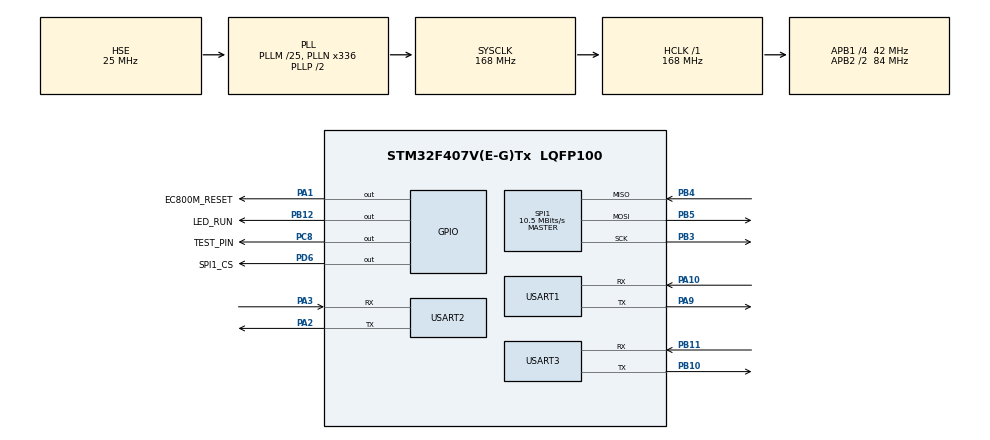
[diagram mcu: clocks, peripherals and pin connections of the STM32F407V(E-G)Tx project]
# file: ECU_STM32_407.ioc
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Dma.Request0=USART1_TX
Dma.Request1=USART2_TX
Dma.Request2=USART3_TX
Dma.USART1_TX.0.Direction=DMA_MEMORY_TO_PERIPH
Dma.USART1_TX.0.FIFOMode=DMA_FIFOMODE_DISABLE
Dma.USART1_TX.0.Instance=DMA2_Stream7
Dma.USART1_TX.0.MemDataAlignment=DMA_MDATAALIGN_BYTE
Dma.USART1_TX.0.MemInc=DMA_MINC_ENABLE
Dma.USART1_TX.0.Mode=DMA_NORMAL
Dma.USART1_TX.0.PeriphDataAlignment=DMA_PDATAALIGN_BYTE
Dma.USART1_TX.0.PeriphInc=DMA_PINC_DISABLE
Dma.USART1_TX.0.Priority=DMA_PRIORITY_LOW
Dma.USART2_TX.1.Direction=DMA_MEMORY_TO_PERIPH
Dma.USART2_TX.1.FIFOMode=DMA_FIFOMODE_DISABLE
Dma.USART2_TX.1.Instance=DMA1_Stream6
Dma.USART2_TX.1.MemDataAlignment=DMA_MDATAALIGN_BYTE
Dma.USART2_TX.1.MemInc=DMA_MINC_ENABLE
Dma.USART2_TX.1.Mode=DMA_NORMAL
Dma.USART2_TX.1.PeriphDataAlignment=DMA_PDATAALIGN_BYTE
Dma.USART2_TX.1.PeriphInc=DMA_PINC_DISABLE
Dma.USART2_TX.1.Priority=DMA_PRIORITY_LOW
Dma.USART3_TX.2.Direction=DMA_MEMORY_TO_PERIPH
Dma.USART3_TX.2.FIFOMode=DMA_FIFOMODE_DISABLE
Dma.USART3_TX.2.Instance=DMA1_Stream3
Dma.USART3_TX.2.MemDataAlignment=DMA_MDATAALIGN_BYTE
Dma.USART3_TX.2.MemInc=DMA_MINC_ENABLE
Dma.USART3_TX.2.Mode=DMA_NORMAL
Dma.USART3_TX.2.PeriphDataAlignment=DMA_PDATAALIGN_BYTE
Dma.USART3_TX.2.PeriphInc=DMA_PINC_DISABLE
Dma.USART3_TX.2.Priority=DMA_PRIORITY_LOW
FREERTOS.Tasks01=defaultTask,0,128,StartDefaultTask,Default,NULL,Dynamic,NULL,NULL;led_task,-2,128,led_task_handle,Default,NULL,Dynamic,NULL,NULL
FREERTOS.configTIMER_TASK_STACK_DEPTH=1024
FREERTOS.configTOTAL_HEAP_SIZE=0x10000
FREERTOS.configUSE_TIMERS=1
Mcu.Family=STM32F4
Mcu.Name=STM32F407V(E-G)Tx
Mcu.Package=LQFP100
NVIC.DMA1_Stream3_IRQn=true\:5\:0\:false\:false\:true\:true\:false\:true\:true
NVIC.DMA1_Stream6_IRQn=true\:5\:0\:false\:false\:true\:true\:false\:true\:true
NVIC.DMA2_Stream7_IRQn=true\:5\:0\:false\:false\:true\:true\:false\:true\:true
NVIC.PriorityGroup=NVIC_PRIORITYGROUP_4
NVIC.SPI1_IRQn=true\:5\:0\:false\:false\:true\:true\:true\:true\:true
NVIC.USART1_IRQn=true\:5\:0\:false\:false\:true\:true\:true\:true\:true
NVIC.USART2_IRQn=true\:5\:0\:false\:false\:true\:true\:true\:true\:true
NVIC.USART3_IRQn=true\:5\:0\:false\:false\:true\:true\:true\:true\:true
PA1.GPIO_Label=EC800M_RESET
PA1.GPIO_ModeDefaultOutputPP=GPIO_MODE_OUTPUT_PP
PA1.GPIO_PuPd=GPIO_PULLUP
PA1.PinState=GPIO_PIN_SET
PA1.Signal=GPIO_Output
PA10.Mode=Asynchronous
PA10.Signal=USART1_RX
PA13.Mode=Serial_Wire
PA13.Signal=SYS_JTMS-SWDIO
PA14.Mode=Serial_Wire
PA14.Signal=SYS_JTCK-SWCLK
PA2.Mode=Asynchronous
PA2.Signal=USART2_TX
PA3.Mode=Asynchronous
PA3.Signal=USART2_RX
PA9.Mode=Asynchronous
PA9.Signal=USART1_TX
PB10.Mode=Asynchronous
PB10.Signal=USART3_TX
PB11.Mode=Asynchronous
PB11.Signal=USART3_RX
PB12.GPIO_Label=LED_RUN
PB12.Signal=GPIO_Output
PB3.Mode=Full_Duplex_Master
PB3.Signal=SPI1_SCK
PB4.Mode=Full_Duplex_Master
PB4.Signal=SPI1_MISO
PB5.Mode=Full_Duplex_Master
PB5.Signal=SPI1_MOSI
PC14-OSC32_IN.Mode=LSE-External-Oscillator
PC14-OSC32_IN.Signal=RCC_OSC32_IN
PC15-OSC32_OUT.Mode=LSE-External-Oscillator
PC15-OSC32_OUT.Signal=RCC_OSC32_OUT
PC8.GPIO_Label=TEST_PIN
PC8.GPIO_PuPd=GPIO_PULLUP
PC8.GPIO_Speed=GPIO_SPEED_FREQ_VERY_HIGH
PC8.Signal=GPIO_Output
PD6.GPIO_Label=SPI1_CS
PD6.GPIO_PuPd=GPIO_PULLUP
PD6.GPIO_Speed=GPIO_SPEED_FREQ_VERY_HIGH
PD6.Signal=GPIO_Output
PH0-OSC_IN.Mode=HSE-External-Oscillator
PH0-OSC_IN.Signal=RCC_OSC_IN
PH1-OSC_OUT.Mode=HSE-External-Oscillator
PH1-OSC_OUT.Signal=RCC_OSC_OUT
ProjectManager.HeapSize=0x800
ProjectManager.StackSize=0x800
ProjectManager.TargetToolchain=EWARM V8.50
RCC.48MHZClocksFreq_Value=48000000
RCC.AHBFreq_Value=168000000
RCC.APB1CLKDivider=RCC_HCLK_DIV4
RCC.APB1Freq_Value=42000000
RCC.APB1TimFreq_Value=84000000
RCC.APB2CLKDivider=RCC_HCLK_DIV2
RCC.APB2Freq_Value=84000000
RCC.APB2TimFreq_Value=168000000
RCC.CortexFreq_Value=168000000
RCC.HCLKFreq_Value=168000000
RCC.HSE_VALUE=25000000
RCC.HSI_VALUE=16000000
RCC.PLLM=25
RCC.PLLN=336
RCC.PLLQ=7
RCC.PLLSourceVirtual=RCC_PLLSOURCE_HSE
RCC.SYSCLKFreq_VALUE=168000000
RCC.SYSCLKSource=RCC_SYSCLKSOURCE_PLLCLK
RCC.VCOOutputFreq_Value=336000000
SPI1.BaudRatePrescaler=SPI_BAUDRATEPRESCALER_8
SPI1.CRCCalculation=SPI_CRCCALCULATION_DISABLE
SPI1.CalculateBaudRate=10.5 MBits/s
SPI1.Direction=SPI_DIRECTION_2LINES
SPI1.Mode=SPI_MODE_MASTER
SPI1.VirtualType=VM_MASTER
USART1.VirtualMode=VM_ASYNC
USART2.VirtualMode=VM_ASYNC
USART3.VirtualMode=VM_ASYNC
VP_FREERTOS_VS_CMSIS_V1.Mode=CMSIS_V1
VP_RTC_VS_RTC_Activate.Mode=RTC_Enabled
VP_RTC_VS_RTC_Calendar.Mode=RTC_Calendar
board=custom

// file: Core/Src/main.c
/* USER CODE BEGIN Header */
/**
  ******************************************************************************
  * @file           : main.c
  * @brief          : Main program body
  ******************************************************************************
  * @attention
  *
  * Copyright (c) 2024 STMicroelectronics.
  * All rights reserved.
  *
  * This software is licensed under terms that can be found in the LICENSE file
  * in the root directory of this software component.
  * If no LICENSE file comes with this software, it is provided AS-IS.
  *
  ******************************************************************************
  */
/* USER CODE END Header */
#include "main.h"
#include "cmsis_os.h"
#include "dma.h"
#include "rtc.h"
#include "spi.h"
#include "usart.h"
#include "gpio.h"

void SystemClock_Config(void);
void MX_FREERTOS_Init(void);

int main(void)
{

  /* MCU Configuration--------------------------------------------------------*/

  /* Reset of all peripherals, Initializes the Flash interface and the Systick. */
  HAL_Init();

  /* Configure the system clock */
  SystemClock_Config();

  /* USER CODE BEGIN SysInit */
  __HAL_RCC_BKPSRAM_CLK_ENABLE();
  /* USER CODE END SysInit */

  /* Initialize all configured peripherals */
  MX_GPIO_Init();
  MX_DMA_Init();
  MX_USART1_UART_Init();
  MX_USART2_UART_Init();
  MX_USART3_UART_Init();
  MX_RTC_Init();
  MX_SPI1_Init();

  /* Call init function for freertos objects (in cmsis_os2.c) */
  MX_FREERTOS_Init();

  /* Start scheduler */
  osKernelStart();

  /* We should never get here as control is now taken by the scheduler */

  /* Infinite loop */
  while (1)
  {

  }
}

void SystemClock_Config(void)
{
  RCC_OscInitTypeDef RCC_OscInitStruct = {0};
  RCC_ClkInitTypeDef RCC_ClkInitStruct = {0};

  /** Configure the main internal regulator output voltage
  */
  __HAL_RCC_PWR_CLK_ENABLE();
  __HAL_PWR_VOLTAGESCALING_CONFIG(PWR_REGULATOR_VOLTAGE_SCALE1);

  /** Initializes the RCC Oscillators according to the specified parameters
  * in the RCC_OscInitTypeDef structure.
  */
  RCC_OscInitStruct.OscillatorType = RCC_OSCILLATORTYPE_LSI|RCC_OSCILLATORTYPE_HSE;
  RCC_OscInitStruct.HSEState = RCC_HSE_ON;
  RCC_OscInitStruct.LSIState = RCC_LSI_ON;
  RCC_OscInitStruct.PLL.PLLState = RCC_PLL_ON;
  RCC_OscInitStruct.PLL.PLLSource = RCC_PLLSOURCE_HSE;
  RCC_OscInitStruct.PLL.PLLM = 25;
  RCC_OscInitStruct.PLL.PLLN = 336;
  RCC_OscInitStruct.PLL.PLLP = RCC_PLLP_DIV2;
  RCC_OscInitStruct.PLL.PLLQ = 7;
  if (HAL_RCC_OscConfig(&RCC_OscInitStruct) != HAL_OK)
  {
    Error_Handler();
  }

  /** Initializes the CPU, AHB and APB buses clocks
  */
  RCC_ClkInitStruct.ClockType = RCC_CLOCKTYPE_HCLK|RCC_CLOCKTYPE_SYSCLK
                              |RCC_CLOCKTYPE_PCLK1|RCC_CLOCKTYPE_PCLK2;
  RCC_ClkInitStruct.SYSCLKSource = RCC_SYSCLKSOURCE_PLLCLK;
  RCC_ClkInitStruct.AHBCLKDivider = RCC_SYSCLK_DIV1;
  RCC_ClkInitStruct.APB1CLKDivider = RCC_HCLK_DIV4;
  RCC_ClkInitStruct.APB2CLKDivider = RCC_HCLK_DIV2;

  if (HAL_RCC_ClockConfig(&RCC_ClkInitStruct, FLASH_LATENCY_5) != HAL_OK)
  {
    Error_Handler();
  }
}

void Error_Handler(void)
{
  __disable_irq();
  while (1)
  {
  }
}

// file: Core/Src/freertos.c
/* USER CODE BEGIN Header */
/**
  ******************************************************************************
  * File Name          : freertos.c
  * Description        : Code for freertos applications
  ******************************************************************************
  * @attention
  *
  * Copyright (c) 2024 STMicroelectronics.
  * All rights reserved.
  *
  * This software is licensed under terms that can be found in the LICENSE file
  * in the root directory of this software component.
  * If no LICENSE file comes with this software, it is provided AS-IS.
  *
  ******************************************************************************
  */
/* USER CODE END Header */

#include "FreeRTOS.h"
#include "task.h"
#include "main.h"
#include "cmsis_os.h"

/* USER CODE BEGIN Includes */
#include "ecu_unit.h"
/* USER CODE END Includes */

osThreadId defaultTaskHandle;
osThreadId led_taskHandle;

void StartDefaultTask(void const * argument);
void led_task_handle(void const * argument);

void MX_FREERTOS_Init(void); /* (MISRA C 2004 rule 8.1) */

/* GetIdleTaskMemory prototype (linked to static allocation support) */
void vApplicationGetIdleTaskMemory( StaticTask_t **ppxIdleTaskTCBBuffer, StackType_t **ppxIdleTaskStackBuffer, uint32_t *pulIdleTaskStackSize );

/* GetTimerTaskMemory prototype (linked to static allocation support) */
void vApplicationGetTimerTaskMemory( StaticTask_t **ppxTimerTaskTCBBuffer, StackType_t **ppxTimerTaskStackBuffer, uint32_t *pulTimerTaskStackSize );

/* USER CODE BEGIN GET_IDLE_TASK_MEMORY */
static StaticTask_t xIdleTaskTCBBuffer;
static StackType_t xIdleStack[configMINIMAL_STACK_SIZE];

void vApplicationGetIdleTaskMemory( StaticTask_t **ppxIdleTaskTCBBuffer, StackType_t **ppxIdleTaskStackBuffer, uint32_t *pulIdleTaskStackSize )
{
  *ppxIdleTaskTCBBuffer = &xIdleTaskTCBBuffer;
  *ppxIdleTaskStackBuffer = &xIdleStack[0];
  *pulIdleTaskStackSize = configMINIMAL_STACK_SIZE;
  /* place for user code */
}
/* USER CODE END GET_IDLE_TASK_MEMORY */

/* USER CODE BEGIN GET_TIMER_TASK_MEMORY */
static StaticTask_t xTimerTaskTCBBuffer;
static StackType_t xTimerStack[configTIMER_TASK_STACK_DEPTH];

void vApplicationGetTimerTaskMemory( StaticTask_t **ppxTimerTaskTCBBuffer, StackType_t **ppxTimerTaskStackBuffer, uint32_t *pulTimerTaskStackSize )
{
  *ppxTimerTaskTCBBuffer = &xTimerTaskTCBBuffer;
  *ppxTimerTaskStackBuffer = &xTimerStack[0];
  *pulTimerTaskStackSize = configTIMER_TASK_STACK_DEPTH;
  /* place for user code */
}
/* USER CODE END GET_TIMER_TASK_MEMORY */

void MX_FREERTOS_Init(void) {

  /* Create the thread(s) */
  /* definition and creation of defaultTask */
  osThreadDef(defaultTask, StartDefaultTask, osPriorityNormal, 0, 128);
  defaultTaskHandle = osThreadCreate(osThread(defaultTask), NULL);

  /* definition and creation of led_task */
  osThreadDef(led_task, led_task_handle, osPriorityLow, 0, 128);
  led_taskHandle = osThreadCreate(osThread(led_task), NULL);

}

void StartDefaultTask(void const * argument)
{
  /* USER CODE BEGIN StartDefaultTask */
  /* Infinite loop */
  ecu_unit_init();
  for(;;)
  {
    ecu_unit_start();
    osDelay(1000);
    osThreadSuspend(osThreadGetId());
  }
  /* USER CODE END StartDefaultTask */
}

void led_task_handle(void const * argument)
{
  /* USER CODE BEGIN led_task_handle */
  /* Infinite loop */
  for(;;)
  {
    HAL_GPIO_TogglePin(LED_RUN_GPIO_Port, LED_RUN_Pin);
    osDelay(500);
  }
  /* USER CODE END led_task_handle */
}
